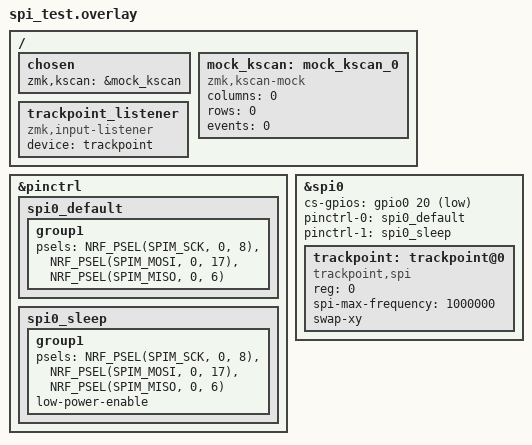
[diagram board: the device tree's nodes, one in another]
/ {
    chosen {
        zmk,kscan = &mock_kscan;
    };

    mock_kscan: mock_kscan_0 {
        compatible = "zmk,kscan-mock";
        columns = <0>;
        rows = <0>;
        events = <0>;
    };
};

&pinctrl {
    spi0_default: spi0_default {
        group1 {
            psels = <NRF_PSEL(SPIM_SCK, 0, 8)>,
                    <NRF_PSEL(SPIM_MOSI, 0, 17)>,
                    <NRF_PSEL(SPIM_MISO, 0, 6)>;
        };
    };
    spi0_sleep: spi0_sleep {
        group1 {
            psels = <NRF_PSEL(SPIM_SCK, 0, 8)>,
                    <NRF_PSEL(SPIM_MOSI, 0, 17)>,
                    <NRF_PSEL(SPIM_MISO, 0, 6)>;
            low-power-enable;
        };
    };
};

&spi0 {
    status = "okay";
    cs-gpios = <&gpio0 20 GPIO_ACTIVE_LOW>;
    pinctrl-0 = <&spi0_default>;
    pinctrl-1 = <&spi0_sleep>;
    pinctrl-names = "default", "sleep";

    trackpoint: trackpoint@0 {
        compatible = "trackpoint,spi";
        reg = <0>;
        spi-max-frequency = <1000000>;
        swap-xy;
    };
};

/ {
    trackpoint_listener {
        compatible = "zmk,input-listener";
        device = <&trackpoint>;
    };
};
